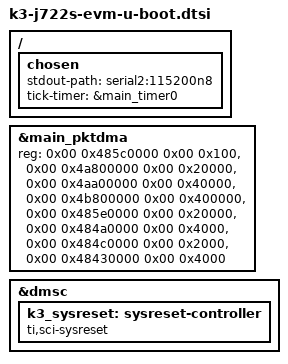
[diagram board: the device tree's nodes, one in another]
// SPDX-License-Identifier: GPL-2.0
/*
 * Common J722S EVM dts file for SPLs
 * Copyright (C) 2023 Texas Instruments Incorporated - https://www.ti.com/
 */

#include "k3-j722s-binman.dtsi"

/ {
	chosen {
		stdout-path = "serial2:115200n8";
		tick-timer = &main_timer0;
	};
};

&main_pktdma {
	reg = <0x00 0x485c0000 0x00 0x100>,
	      <0x00 0x4a800000 0x00 0x20000>,
	      <0x00 0x4aa00000 0x00 0x40000>,
	      <0x00 0x4b800000 0x00 0x400000>,
	      <0x00 0x485e0000 0x00 0x20000>,
	      <0x00 0x484a0000 0x00 0x4000>,
	      <0x00 0x484c0000 0x00 0x2000>,
	      <0x00 0x48430000 0x00 0x4000>;
	reg-names = "gcfg", "rchanrt", "tchanrt", "ringrt",
		    "cfg", "tchan", "rchan", "rflow";
};

&dmsc {
	bootph-pre-ram;
	k3_sysreset: sysreset-controller {
		compatible = "ti,sci-sysreset";
		bootph-pre-ram;
	};
};
